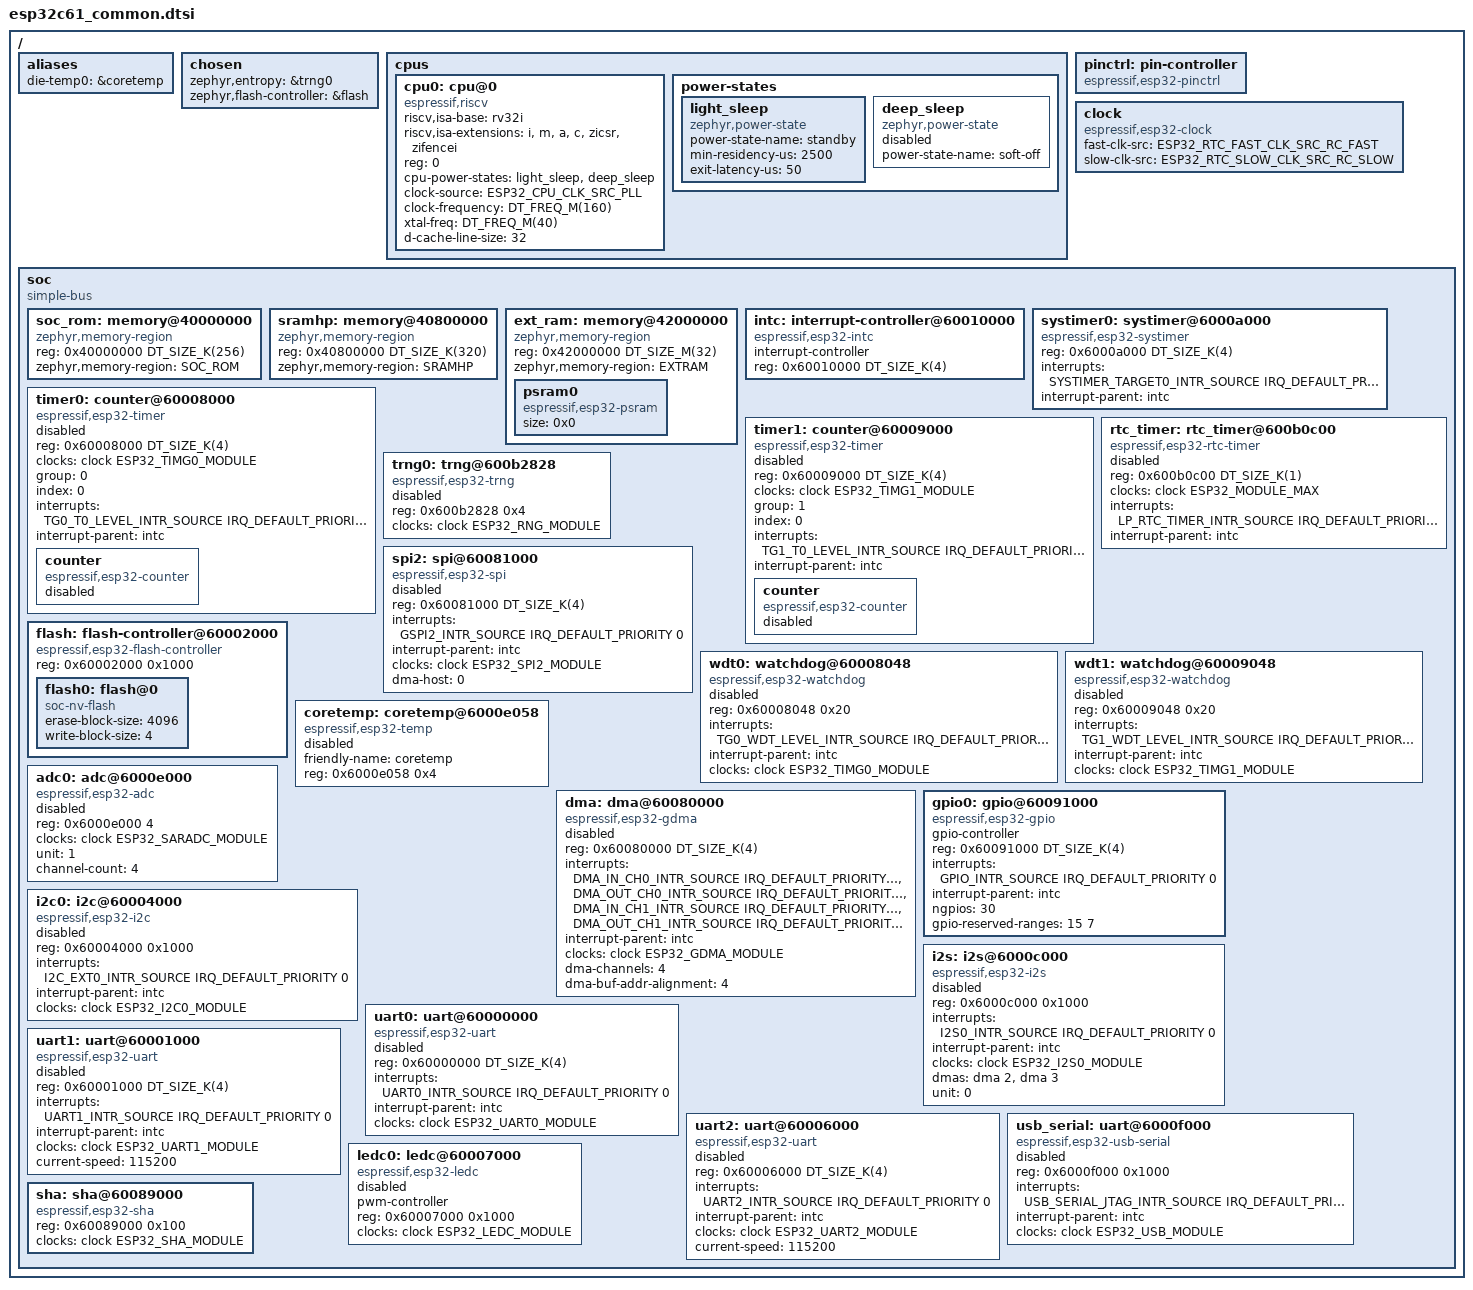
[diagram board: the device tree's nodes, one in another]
/*
 * Copyright (c) 2026 Espressif Systems (Shanghai) Co., Ltd.
 *
 * SPDX-License-Identifier: Apache-2.0
 */
#include <mem.h>
#include <freq.h>
#include <zephyr/dt-bindings/adc/adc.h>
#include <zephyr/dt-bindings/gpio/gpio.h>
#include <zephyr/dt-bindings/i2c/i2c.h>
#include <zephyr/dt-bindings/interrupt-controller/esp-esp32c61-intmux.h>
#include <zephyr/dt-bindings/clock/esp32c61_clock.h>
#include <zephyr/dt-bindings/pinctrl/esp32c61-pinctrl.h>
#include <zephyr/dt-bindings/memory-attr/memory-attr-riscv.h>

/ {
	#address-cells = <1>;
	#size-cells = <1>;

	aliases {
		die-temp0 = &coretemp;
	};

	chosen {
		zephyr,entropy = &trng0;
		zephyr,flash-controller = &flash;
	};

	cpus {
		#address-cells = <1>;
		#size-cells = <0>;

		cpu0: cpu@0 {
			device_type = "cpu";
			compatible = "espressif,riscv", "riscv";
			riscv,isa-base = "rv32i";
			riscv,isa-extensions = "i", "m", "a", "c", "zicsr", "zifencei";
			reg = <0>;
			cpu-power-states = <&light_sleep &deep_sleep>;
			clock-source = <ESP32_CPU_CLK_SRC_PLL>;
			clock-frequency = <DT_FREQ_M(160)>;
			xtal-freq = <DT_FREQ_M(40)>;
			d-cache-line-size = <32>;
		};

		power-states {
			light_sleep: light_sleep {
				compatible = "zephyr,power-state";
				power-state-name = "standby";
				min-residency-us = <2500>;
				exit-latency-us = <50>;
			};

			deep_sleep: deep_sleep {
				/* Deep sleep must be entered using pm_state_force()
				 * or sys_poweroff() calls only
				 */
				compatible = "zephyr,power-state";
				power-state-name = "soft-off";
				status = "disabled";
			};
		};
	};

	pinctrl: pin-controller {
		compatible = "espressif,esp32-pinctrl";
		status = "okay";
	};

	clock: clock {
		compatible = "espressif,esp32-clock";
		fast-clk-src = <ESP32_RTC_FAST_CLK_SRC_RC_FAST>;
		slow-clk-src = <ESP32_RTC_SLOW_CLK_SRC_RC_SLOW>;
		#clock-cells = <1>;
		status = "okay";
	};

	soc {
		#address-cells = <1>;
		#size-cells = <1>;
		compatible = "simple-bus";
		ranges;

		/* ROM code region, contains the libc and utility functions */
		soc_rom: memory@40000000 {
			compatible = "zephyr,memory-region";
			reg = <0x40000000 DT_SIZE_K(256)>;
			zephyr,memory-region = "SOC_ROM";
		};

		sramhp: memory@40800000 {
			compatible = "zephyr,memory-region", "mmio-sram";
			reg = <0x40800000 DT_SIZE_K(320)>;
			zephyr,memory-region = "SRAMHP";
		};

		ext_ram: memory@42000000 {
			compatible = "zephyr,memory-region";
			reg = <0x42000000 DT_SIZE_M(32)>;
			zephyr,memory-region = "EXTRAM";

			psram0: psram0 {
				compatible = "espressif,esp32-psram";
				size = <0x0>;
			};
		};

		intc: interrupt-controller@60010000 {
			compatible = "espressif,esp32-intc";
			#address-cells = <0>;
			#interrupt-cells = <3>;
			interrupt-controller;
			reg = <0x60010000 DT_SIZE_K(4)>;
			status = "okay";
		};

		systimer0: systimer@6000a000 {
			compatible = "espressif,esp32-systimer";
			reg = <0x6000a000 DT_SIZE_K(4)>;
			interrupts = <SYSTIMER_TARGET0_INTR_SOURCE IRQ_DEFAULT_PRIORITY 0>;
			interrupt-parent = <&intc>;
			status = "okay";
		};

		timer0: counter@60008000 {
			compatible = "espressif,esp32-timer";
			reg = <0x60008000 DT_SIZE_K(4)>;
			clocks = <&clock ESP32_TIMG0_MODULE>;
			group = <0>;
			index = <0>;
			interrupts = <TG0_T0_LEVEL_INTR_SOURCE IRQ_DEFAULT_PRIORITY 0>;
			interrupt-parent = <&intc>;
			status = "disabled";

			counter {
				compatible = "espressif,esp32-counter";
				status = "disabled";
			};
		};

		timer1: counter@60009000 {
			compatible = "espressif,esp32-timer";
			reg = <0x60009000 DT_SIZE_K(4)>;
			clocks = <&clock ESP32_TIMG1_MODULE>;
			group = <1>;
			index = <0>;
			interrupts = <TG1_T0_LEVEL_INTR_SOURCE IRQ_DEFAULT_PRIORITY 0>;
			interrupt-parent = <&intc>;
			status = "disabled";

			counter {
				compatible = "espressif,esp32-counter";
				status = "disabled";
			};
		};

		rtc_timer: rtc_timer@600b0c00 {
			compatible = "espressif,esp32-rtc-timer";
			reg = <0x600b0c00 DT_SIZE_K(1)>;
			clocks = <&clock ESP32_MODULE_MAX>;
			interrupts = <LP_RTC_TIMER_INTR_SOURCE IRQ_DEFAULT_PRIORITY 0>;
			interrupt-parent = <&intc>;
			status = "disabled";
		};

		trng0: trng@600b2828 {
			compatible = "espressif,esp32-trng";
			reg = <0x600b2828 0x4>;
			clocks = <&clock ESP32_RNG_MODULE>;
			status = "disabled";
		};

		spi2: spi@60081000 {
			compatible = "espressif,esp32-spi";
			reg = <0x60081000 DT_SIZE_K(4)>;
			interrupts = <GSPI2_INTR_SOURCE IRQ_DEFAULT_PRIORITY 0>;
			interrupt-parent = <&intc>;
			clocks = <&clock ESP32_SPI2_MODULE>;
			dma-host = <0>;
			status = "disabled";
		};

		wdt0: watchdog@60008048 {
			compatible = "espressif,esp32-watchdog";
			reg = <0x60008048 0x20>;
			interrupts = <TG0_WDT_LEVEL_INTR_SOURCE IRQ_DEFAULT_PRIORITY 0>;
			interrupt-parent = <&intc>;
			clocks = <&clock ESP32_TIMG0_MODULE>;
			status = "disabled";
		};

		wdt1: watchdog@60009048 {
			compatible = "espressif,esp32-watchdog";
			reg = <0x60009048 0x20>;
			interrupts = <TG1_WDT_LEVEL_INTR_SOURCE IRQ_DEFAULT_PRIORITY 0>;
			interrupt-parent = <&intc>;
			clocks = <&clock ESP32_TIMG1_MODULE>;
			status = "disabled";
		};

		flash: flash-controller@60002000 {
			compatible = "espressif,esp32-flash-controller";
			reg = <0x60002000 0x1000>;

			#address-cells = <1>;
			#size-cells = <1>;
			ranges;

			flash0: flash@0 {
				compatible = "soc-nv-flash";
				erase-block-size = <4096>;
				write-block-size = <4>;
				#address-cells = <1>;
				#size-cells = <1>;
				/* reg and ranges are specified in SOC/SIP dtsi */
			};
		};

		coretemp: coretemp@6000e058 {
			compatible = "espressif,esp32-temp";
			friendly-name = "coretemp";
			reg = <0x6000e058 0x4>;
			status = "disabled";
		};

		adc0: adc@6000e000 {
			compatible = "espressif,esp32-adc";
			reg = <0x6000e000 4>;
			clocks = <&clock ESP32_SARADC_MODULE>;
			unit = <1>;
			channel-count = <4>;
			#io-channel-cells = <1>;
			status = "disabled";
		};

		dma: dma@60080000 {
			compatible = "espressif,esp32-gdma";
			reg = <0x60080000 DT_SIZE_K(4)>;
			#dma-cells = <1>;
			interrupts = <DMA_IN_CH0_INTR_SOURCE IRQ_DEFAULT_PRIORITY 0>,
				     <DMA_OUT_CH0_INTR_SOURCE IRQ_DEFAULT_PRIORITY 0>,
				     <DMA_IN_CH1_INTR_SOURCE IRQ_DEFAULT_PRIORITY 0>,
				     <DMA_OUT_CH1_INTR_SOURCE IRQ_DEFAULT_PRIORITY 0>;
			interrupt-parent = <&intc>;
			clocks = <&clock ESP32_GDMA_MODULE>;
			dma-channels = <4>;
			dma-buf-addr-alignment = <4>;
			status = "disabled";
		};

		gpio0: gpio@60091000 {
			compatible = "espressif,esp32-gpio";
			gpio-controller;
			#gpio-cells = <2>;
			reg = <0x60091000 DT_SIZE_K(4)>;
			interrupts = <GPIO_INTR_SOURCE IRQ_DEFAULT_PRIORITY 0>;
			interrupt-parent = <&intc>;
			ngpios = <30>;
			/* GPIO15-21 are the MSPI flash pads (CS0..MOSI) */
			gpio-reserved-ranges = <15 7>;
		};

		i2c0: i2c@60004000 {
			compatible = "espressif,esp32-i2c";
			#address-cells = <1>;
			#size-cells = <0>;
			reg = <0x60004000 0x1000>;
			interrupts = <I2C_EXT0_INTR_SOURCE IRQ_DEFAULT_PRIORITY 0>;
			interrupt-parent = <&intc>;
			clocks = <&clock ESP32_I2C0_MODULE>;
			status = "disabled";
		};

		i2s: i2s@6000c000 {
			compatible = "espressif,esp32-i2s";
			#address-cells = <1>;
			#size-cells = <0>;
			reg = <0x6000c000 0x1000>;
			interrupts = <I2S0_INTR_SOURCE IRQ_DEFAULT_PRIORITY 0>;
			interrupt-parent = <&intc>;
			clocks = <&clock ESP32_I2S0_MODULE>;
			dmas = <&dma 2>, <&dma 3>;
			dma-names = "rx", "tx";
			unit = <0>;
			status = "disabled";
		};

		uart0: uart@60000000 {
			compatible = "espressif,esp32-uart";
			reg = <0x60000000 DT_SIZE_K(4)>;
			status = "disabled";
			interrupts = <UART0_INTR_SOURCE IRQ_DEFAULT_PRIORITY 0>;
			interrupt-parent = <&intc>;
			clocks = <&clock ESP32_UART0_MODULE>;
		};

		uart1: uart@60001000 {
			compatible = "espressif,esp32-uart";
			reg = <0x60001000 DT_SIZE_K(4)>;
			status = "disabled";
			interrupts = <UART1_INTR_SOURCE IRQ_DEFAULT_PRIORITY 0>;
			interrupt-parent = <&intc>;
			clocks = <&clock ESP32_UART1_MODULE>;
			current-speed = <115200>;
		};

		uart2: uart@60006000 {
			compatible = "espressif,esp32-uart";
			reg = <0x60006000 DT_SIZE_K(4)>;
			status = "disabled";
			interrupts = <UART2_INTR_SOURCE IRQ_DEFAULT_PRIORITY 0>;
			interrupt-parent = <&intc>;
			clocks = <&clock ESP32_UART2_MODULE>;
			current-speed = <115200>;
		};

		usb_serial: uart@6000f000 {
			compatible = "espressif,esp32-usb-serial";
			reg = <0x6000f000 0x1000>;
			status = "disabled";
			interrupts = <USB_SERIAL_JTAG_INTR_SOURCE IRQ_DEFAULT_PRIORITY 0>;
			interrupt-parent = <&intc>;
			clocks = <&clock ESP32_USB_MODULE>;
		};

		ledc0: ledc@60007000 {
			compatible = "espressif,esp32-ledc";
			pwm-controller;
			#pwm-cells = <3>;
			reg = <0x60007000 0x1000>;
			clocks = <&clock ESP32_LEDC_MODULE>;
			status = "disabled";
		};

		sha: sha@60089000 {
			compatible = "espressif,esp32-sha";
			reg = <0x60089000 0x100>;
			clocks = <&clock ESP32_SHA_MODULE>;
			status = "okay";
		};
	};
};
